# Espressif register map
File version: 1.0
CPU: Xtensa LX6 1, little endian, no MPU, FPU, 3 interrupt priority bits
Registers are 32-bit, access not given, reset 0x0 unless marked. A register's access mark holds for its fields unless they carry their own. Offsets are from the block's base; [hi:lo] are bit positions; {n}, {i} and the like mark numbered series.

## SENS
Base 0x3FF48800
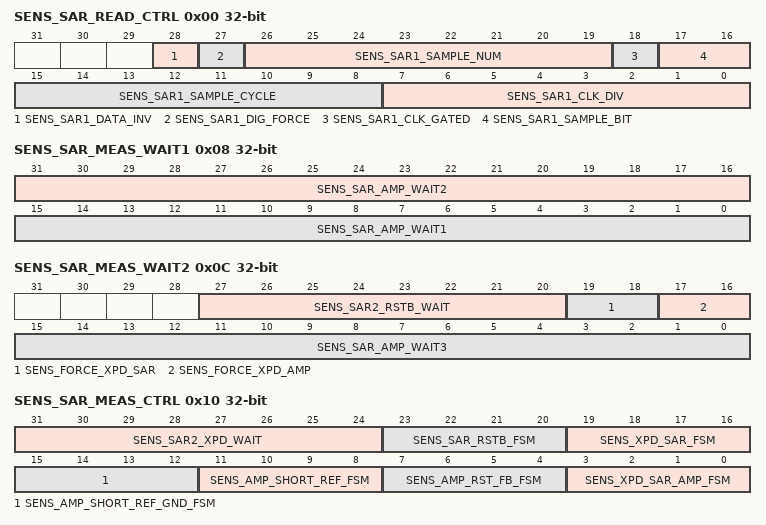
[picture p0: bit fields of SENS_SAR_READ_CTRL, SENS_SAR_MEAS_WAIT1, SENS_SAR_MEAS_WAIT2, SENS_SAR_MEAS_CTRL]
0x00 SENS_SAR_READ_CTRL
  [28] SENS_SAR1_DATA_INV, [27] SENS_SAR1_DIG_FORCE, [26:19] SENS_SAR1_SAMPLE_NUM, [18] SENS_SAR1_CLK_GATED, [17:16] SENS_SAR1_SAMPLE_BIT, [15:8] SENS_SAR1_SAMPLE_CYCLE, [7:0] SENS_SAR1_CLK_DIV
0x04 SENS_SAR_READ_STATUS1
  [31:0] SENS_SAR1_READER_STATUS
0x08 SENS_SAR_MEAS_WAIT1
  [31:16] SENS_SAR_AMP_WAIT2, [15:0] SENS_SAR_AMP_WAIT1
0x0C SENS_SAR_MEAS_WAIT2
  [27:20] SENS_SAR2_RSTB_WAIT, [19:18] SENS_FORCE_XPD_SAR, [17:16] SENS_FORCE_XPD_AMP, [15:0] SENS_SAR_AMP_WAIT3
0x10 SENS_SAR_MEAS_CTRL
  [31:24] SENS_SAR2_XPD_WAIT, [23:20] SENS_SAR_RSTB_FSM, [19:16] SENS_XPD_SAR_FSM, [15:12] SENS_AMP_SHORT_REF_GND_FSM, [11:8] SENS_AMP_SHORT_REF_FSM, [7:4] SENS_AMP_RST_FB_FSM, [3:0] SENS_XPD_SAR_AMP_FSM
0x14 SENS_SAR_READ_STATUS2
  [31:0] SENS_SAR2_READER_STATUS
{0x18+4i} SENS_ULP_CP_SLEEP_CYC{i} (i=0..4)
  [31:0] SENS_SLEEP_CYCLES_S{i}
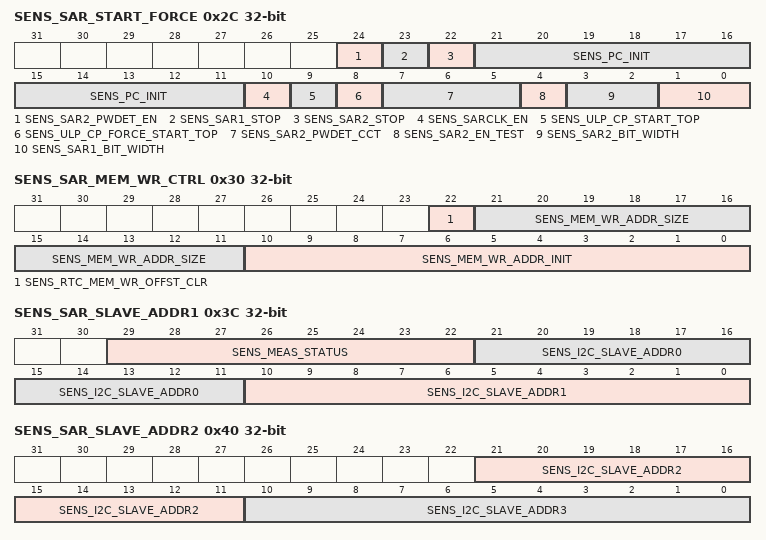
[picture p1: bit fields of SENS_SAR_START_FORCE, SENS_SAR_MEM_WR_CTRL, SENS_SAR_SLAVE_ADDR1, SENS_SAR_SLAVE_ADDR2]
0x2C SENS_SAR_START_FORCE
  [24] SENS_SAR2_PWDET_EN, [23] SENS_SAR1_STOP, [22] SENS_SAR2_STOP, [21:11] SENS_PC_INIT, [10] SENS_SARCLK_EN, [9] SENS_ULP_CP_START_TOP, [8] SENS_ULP_CP_FORCE_START_TOP, [7:5] SENS_SAR2_PWDET_CCT, [4] SENS_SAR2_EN_TEST, [3:2] SENS_SAR2_BIT_WIDTH, [1:0] SENS_SAR1_BIT_WIDTH
0x30 SENS_SAR_MEM_WR_CTRL
  [22] SENS_RTC_MEM_WR_OFFST_CLR, [21:11] SENS_MEM_WR_ADDR_SIZE, [10:0] SENS_MEM_WR_ADDR_INIT
0x34 SENS_SAR_ATTEN1
  [31:0] SENS_SAR1_ATTEN
0x38 SENS_SAR_ATTEN2
  [31:0] SENS_SAR2_ATTEN
0x3C SENS_SAR_SLAVE_ADDR1
  [29:22] SENS_MEAS_STATUS, [21:11] SENS_I2C_SLAVE_ADDR0, [10:0] SENS_I2C_SLAVE_ADDR1
0x40 SENS_SAR_SLAVE_ADDR2
  [21:11] SENS_I2C_SLAVE_ADDR2, [10:0] SENS_I2C_SLAVE_ADDR3
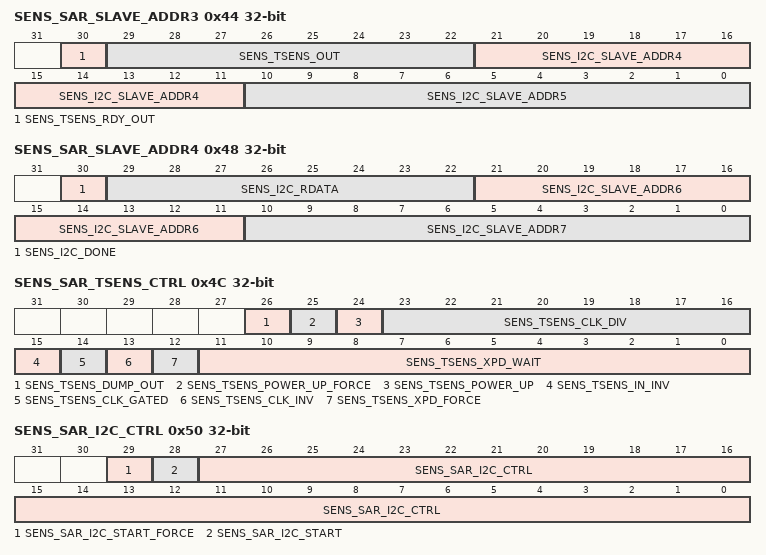
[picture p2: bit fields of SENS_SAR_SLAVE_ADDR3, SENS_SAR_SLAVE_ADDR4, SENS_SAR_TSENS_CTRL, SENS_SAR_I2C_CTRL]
0x44 SENS_SAR_SLAVE_ADDR3
  [30] SENS_TSENS_RDY_OUT, [29:22] SENS_TSENS_OUT, [21:11] SENS_I2C_SLAVE_ADDR4, [10:0] SENS_I2C_SLAVE_ADDR5
0x48 SENS_SAR_SLAVE_ADDR4
  [30] SENS_I2C_DONE, [29:22] SENS_I2C_RDATA, [21:11] SENS_I2C_SLAVE_ADDR6, [10:0] SENS_I2C_SLAVE_ADDR7
0x4C SENS_SAR_TSENS_CTRL
  [26] SENS_TSENS_DUMP_OUT, [25] SENS_TSENS_POWER_UP_FORCE, [24] SENS_TSENS_POWER_UP, [23:16] SENS_TSENS_CLK_DIV, [15] SENS_TSENS_IN_INV, [14] SENS_TSENS_CLK_GATED, [13] SENS_TSENS_CLK_INV, [12] SENS_TSENS_XPD_FORCE, [11:0] SENS_TSENS_XPD_WAIT
0x50 SENS_SAR_I2C_CTRL
  [29] SENS_SAR_I2C_START_FORCE, [28] SENS_SAR_I2C_START, [27:0] SENS_SAR_I2C_CTRL
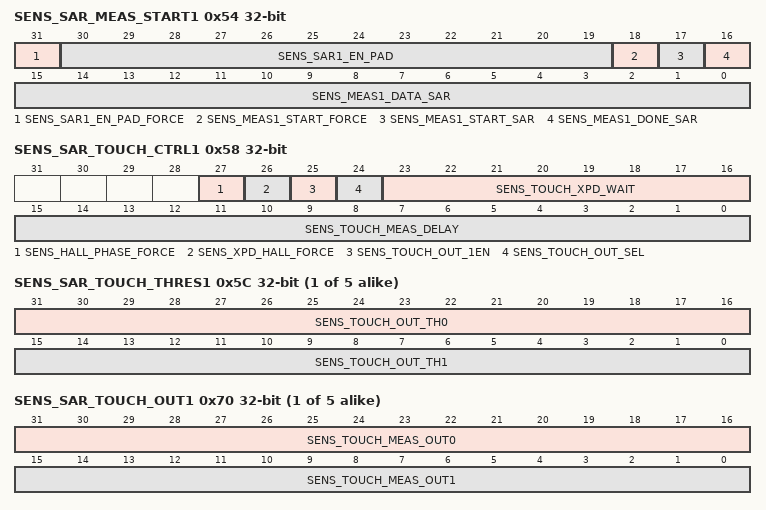
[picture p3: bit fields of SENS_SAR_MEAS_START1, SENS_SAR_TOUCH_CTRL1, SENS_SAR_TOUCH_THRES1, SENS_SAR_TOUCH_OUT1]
0x54 SENS_SAR_MEAS_START1
  [31] SENS_SAR1_EN_PAD_FORCE, [30:19] SENS_SAR1_EN_PAD, [18] SENS_MEAS1_START_FORCE, [17] SENS_MEAS1_START_SAR, [16] SENS_MEAS1_DONE_SAR, [15:0] SENS_MEAS1_DATA_SAR
0x58 SENS_SAR_TOUCH_CTRL1
  [27] SENS_HALL_PHASE_FORCE, [26] SENS_XPD_HALL_FORCE, [25] SENS_TOUCH_OUT_1EN, [24] SENS_TOUCH_OUT_SEL, [23:16] SENS_TOUCH_XPD_WAIT, [15:0] SENS_TOUCH_MEAS_DELAY
{0x58+4i} SENS_SAR_TOUCH_THRES{i} (i=1..5)
  [31:16] SENS_TOUCH_OUT_TH{2i-2}, [15:0] SENS_TOUCH_OUT_TH{2i-1}
{0x6C+4i} SENS_SAR_TOUCH_OUT{i} (i=1..5)
  [31:16] SENS_TOUCH_MEAS_OUT{2i-2}, [15:0] SENS_TOUCH_MEAS_OUT{2i-1}
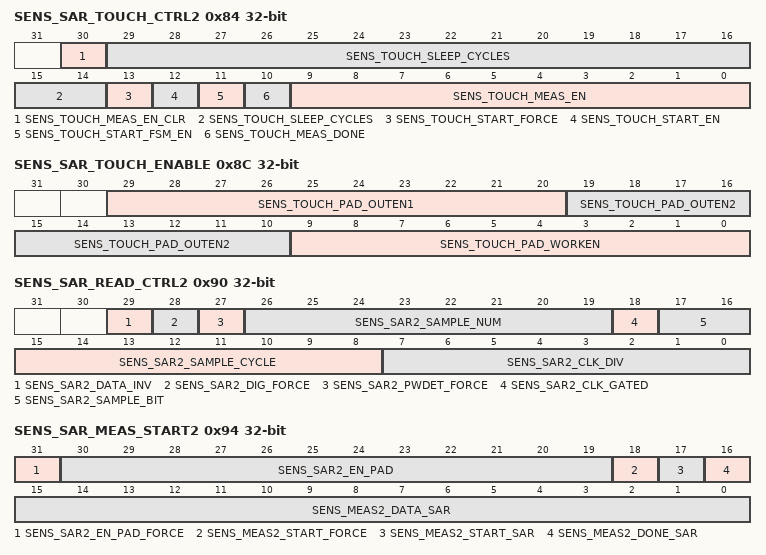
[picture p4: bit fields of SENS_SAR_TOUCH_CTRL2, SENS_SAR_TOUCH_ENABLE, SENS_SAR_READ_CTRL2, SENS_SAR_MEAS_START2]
0x84 SENS_SAR_TOUCH_CTRL2
  [30] SENS_TOUCH_MEAS_EN_CLR, [29:14] SENS_TOUCH_SLEEP_CYCLES, [13] SENS_TOUCH_START_FORCE, [12] SENS_TOUCH_START_EN, [11] SENS_TOUCH_START_FSM_EN, [10] SENS_TOUCH_MEAS_DONE, [9:0] SENS_TOUCH_MEAS_EN
0x8C SENS_SAR_TOUCH_ENABLE
  [29:20] SENS_TOUCH_PAD_OUTEN1, [19:10] SENS_TOUCH_PAD_OUTEN2, [9:0] SENS_TOUCH_PAD_WORKEN
0x90 SENS_SAR_READ_CTRL2
  [29] SENS_SAR2_DATA_INV, [28] SENS_SAR2_DIG_FORCE, [27] SENS_SAR2_PWDET_FORCE, [26:19] SENS_SAR2_SAMPLE_NUM, [18] SENS_SAR2_CLK_GATED, [17:16] SENS_SAR2_SAMPLE_BIT, [15:8] SENS_SAR2_SAMPLE_CYCLE, [7:0] SENS_SAR2_CLK_DIV
0x94 SENS_SAR_MEAS_START2
  [31] SENS_SAR2_EN_PAD_FORCE, [30:19] SENS_SAR2_EN_PAD, [18] SENS_MEAS2_START_FORCE, [17] SENS_MEAS2_START_SAR, [16] SENS_MEAS2_DONE_SAR, [15:0] SENS_MEAS2_DATA_SAR
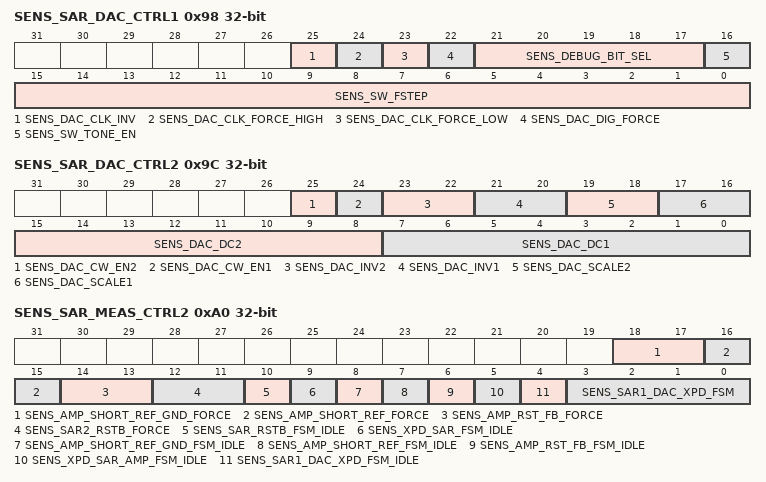
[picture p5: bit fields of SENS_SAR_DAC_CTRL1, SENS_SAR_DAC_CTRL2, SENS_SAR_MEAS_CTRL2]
0x98 SENS_SAR_DAC_CTRL1
  [25] SENS_DAC_CLK_INV, [24] SENS_DAC_CLK_FORCE_HIGH, [23] SENS_DAC_CLK_FORCE_LOW, [22] SENS_DAC_DIG_FORCE, [21:17] SENS_DEBUG_BIT_SEL, [16] SENS_SW_TONE_EN, [15:0] SENS_SW_FSTEP
0x9C SENS_SAR_DAC_CTRL2
  [25] SENS_DAC_CW_EN2, [24] SENS_DAC_CW_EN1, [23:22] SENS_DAC_INV2, [21:20] SENS_DAC_INV1, [19:18] SENS_DAC_SCALE2, [17:16] SENS_DAC_SCALE1, [15:8] SENS_DAC_DC2, [7:0] SENS_DAC_DC1
0xA0 SENS_SAR_MEAS_CTRL2
  [18:17] SENS_AMP_SHORT_REF_GND_FORCE, [16:15] SENS_AMP_SHORT_REF_FORCE, [14:13] SENS_AMP_RST_FB_FORCE, [12:11] SENS_SAR2_RSTB_FORCE, [10] SENS_SAR_RSTB_FSM_IDLE, [9] SENS_XPD_SAR_FSM_IDLE, [8] SENS_AMP_SHORT_REF_GND_FSM_IDLE, [7] SENS_AMP_SHORT_REF_FSM_IDLE, [6] SENS_AMP_RST_FB_FSM_IDLE, [5] SENS_XPD_SAR_AMP_FSM_IDLE, [4] SENS_SAR1_DAC_XPD_FSM_IDLE, [3:0] SENS_SAR1_DAC_XPD_FSM
0xF8 SENS_SAR_NOUSE
0xFC SENS_SARDATE
  [27:0] SENS_SAR_DATE
